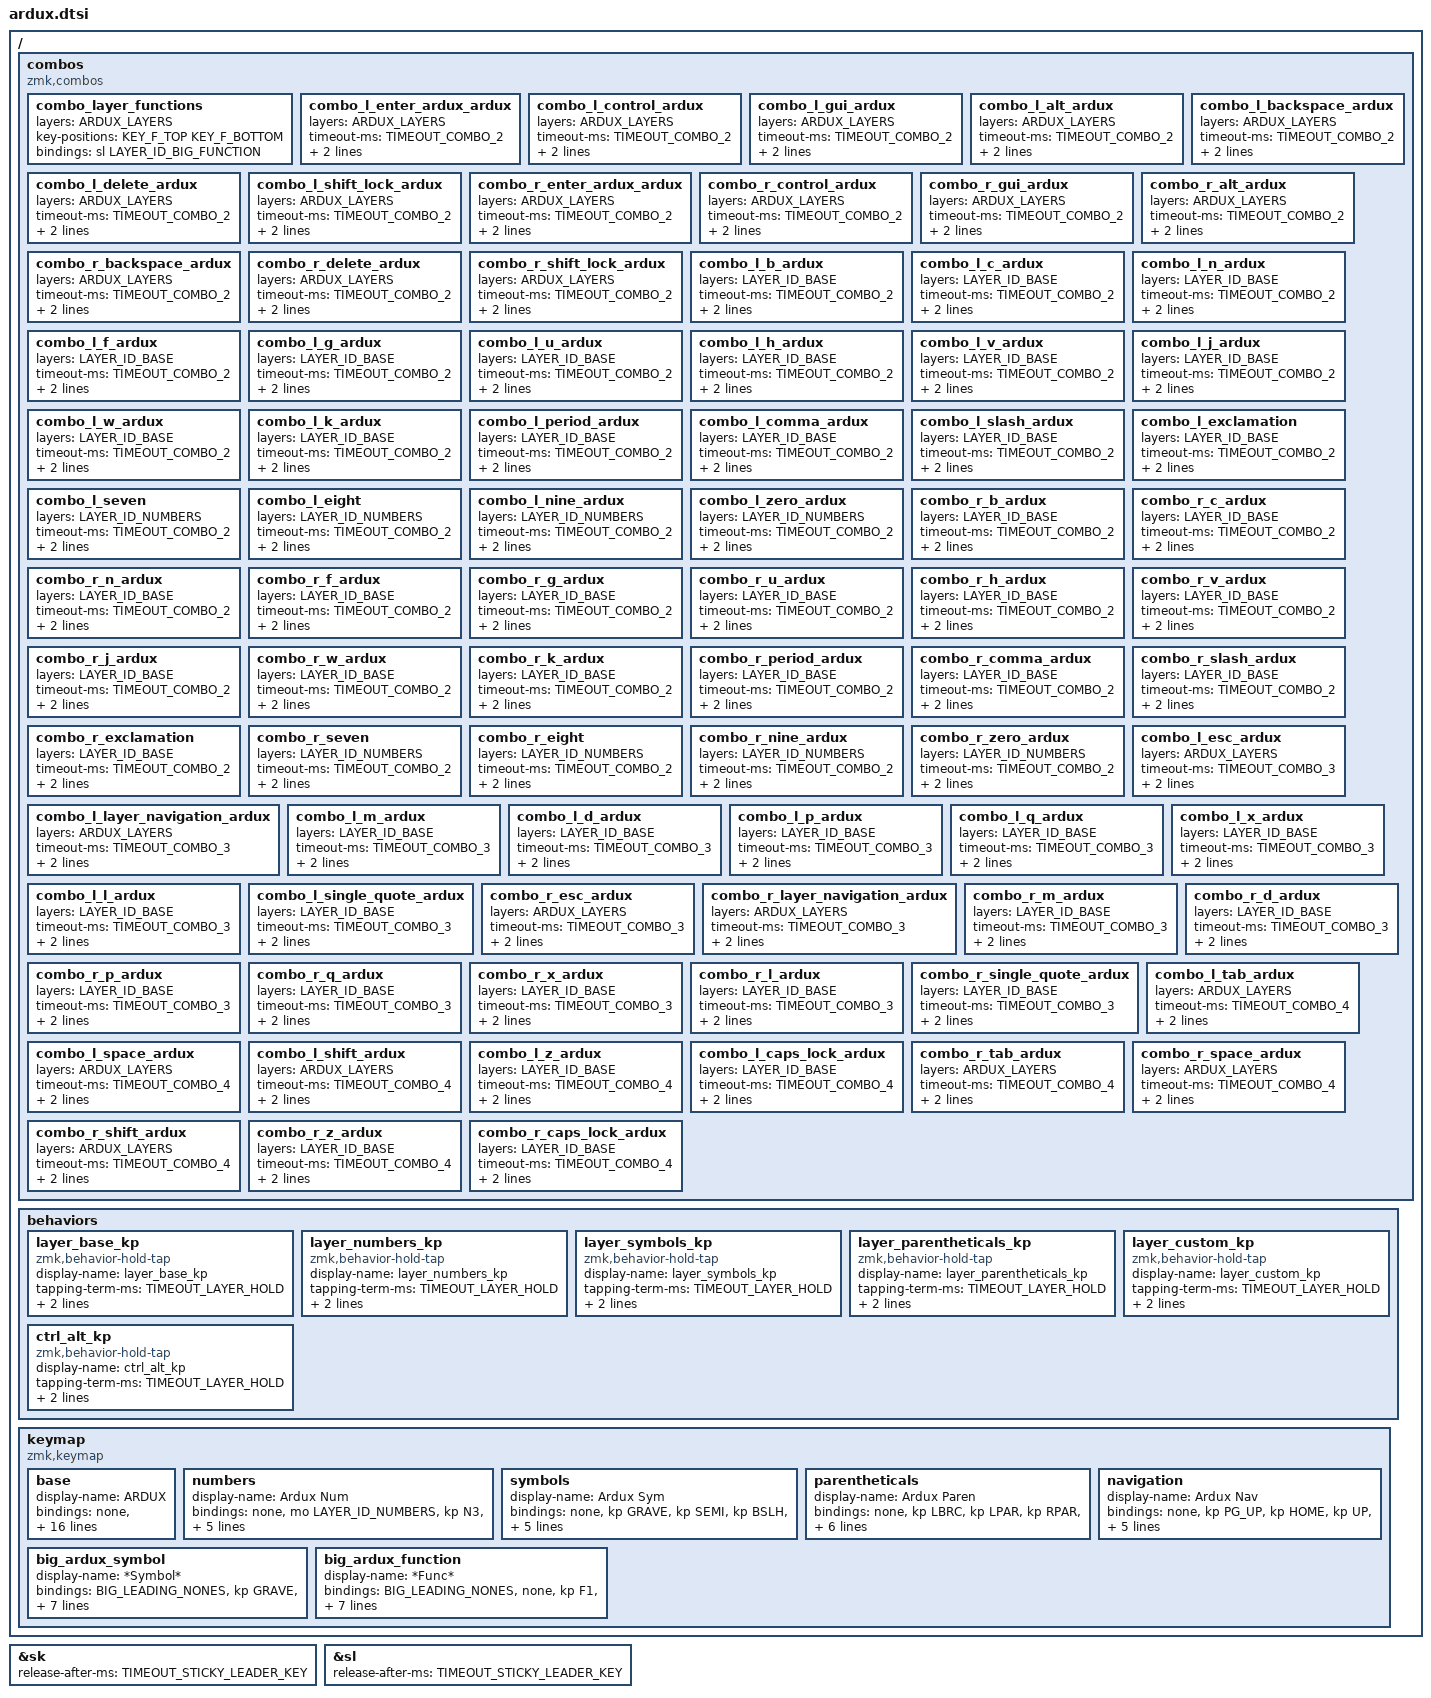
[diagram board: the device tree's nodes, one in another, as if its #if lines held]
/*
 * Copyright (c) 2021 Mike "KemoNine" Crosson
 *
 * SPDX-License-Identifier: MIT
 */

#include <behaviors.dtsi>
#include <dt-bindings/zmk/keys.h>
#include <dt-bindings/zmk/outputs.h>

/*****************************************
 * Macros for filling in "&none" in the right places in the keymap for re-use needs
 *****************************************/
#define NONE0(X)
#define NONE1(X) X
#define NONE2(X) NONE1(X) X
#define NONE3(X) NONE2(X) X
#define NONE4(X) NONE3(X) X
#define NONE5(X) NONE4(X) X
#define NONE6(X) NONE5(X) X
#define NONE7(X) NONE6(X) X
#define NONE8(X) NONE7(X) X
#define NONE9(X) NONE8(X) X
#define NONE10(X) NONE9(X) X

#define NONE(HUNDREDS,TENS,ONES) \
  NONE##HUNDREDS(NONE10(NONE10(&none))) \
  NONE##TENS(NONE10(&none)) \
  NONE##ONES(&none)

/*****************************************
 * ARDUX website : https://www.ardux.io
 * Primary reference : https://www.ardux.io/_FILES/images/ARDUX.jpg
*****************************************/

/*****************************************
 * Setting up ARDUX comboing
 *   - Enabled right OR left handed orientation
 *   - Please note: A/E key positions should be on your INDEX finger
 *     - The online reference is for right handed use
 *     - When using the ARDUX layout left handed you'll want to ensure your keypositions are flipped along the Y axis
 *   - Update/adjust the key positions using your boards keymap 
 *     - See below for additional details
 *   - YOU MUST SET THE FOLLOWING CONFIG VALUES FOR THIS SETUP TO WORK PROPERLY IN YOUR BOARDS .conf FILE
 *     - CONFIG_ZMK_COMBO_MAX_COMBOS_PER_KEY=16
 *     - CONFIG_ZMK_COMBO_MAX_KEYS_PER_COMBO=8
 *     - CONFIG_ZMK_COMBO_MAX_PRESSED_COMBOS=8
 *****************************************/

/*****************************************
 * Define which layout you want to use
 *  ONLY ENABLE ONE OF THESE
*****************************************/
//#define ARDUX_RIGHT 1
//#define ARDUX_LEFT 1
//#define ARDUX_BIG 1
// If you use COLEMAK as your standard keyboard layout, you may want this
//     This define will make base ardux keys and N more in line with COLEMAK
// #define ARDUX_COLEMAK 1

/*****************************************
 * Define key positions used for combos
 * These definitions are used to define the various ARDUX combos
 * 
 * Please see the documentation on "combos" for details on how to find the proper key positions
 *
 * Default key positions are for a generic 4x2 keyboard and should NOT be used outright
 * DEFINE these definitions in your boards keymap BEFORE including ardux.dtsi
*****************************************/
// ARTS Row
// #define KEY_A 0
// #define KEY_R 1
// #define KEY_T 2
// #define KEY_S 3
// EYIO Row
// #define KEY_E 4
// #define KEY_Y 5
// #define KEY_I 6
// #define KEY_O 7
// Big ardux F1-12 layer keys for combo
// #define KEY_F_TOP -1
// #define KEY_F_BOTTOM -1


// Big ardux F1-12 layer keys for combo
// If using these, update offsets
// #define KEY_F_TOP 5
// #define KEY_F_BOTTOM 17



/*****************************************
 * Define custom BT layer extra keys
 *
 * You can override the 2 blank keys on the BT select layer by copy/pasting the below into your keymap
 *     *before* including the ardux.dtsfile
 * Once added to your keymap you can adjust these 2 keys as you see fit
*****************************************/
#if !defined ARDUX_BT_TOP
#define ARDUX_BT_TOP &out OUT_BLE
#endif
#if !defined ARDUX_BT_BOTTOM
#define ARDUX_BT_BOTTOM &out OUT_USB
#endif

/*****************************************
 * Define how long it takes for the combos/holds to 'time out'
 * See documentation on "combos" for more detail
 * THE COMBO TIMEOUTS MUST BE THE SAME
 *    https://github.com/zmkfirmware/zmk/issues/905
 *****************************************/
#if !defined TIMEOUT_COMBO_2
#define TIMEOUT_COMBO_2 50
#endif
#if !defined TIMEOUT_COMBO_3
#define TIMEOUT_COMBO_3 50
#endif
#if !defined TIMEOUT_COMBO_4
#define TIMEOUT_COMBO_4 50
#endif
#if !defined TIMEOUT_LAYER_HOLD
#define TIMEOUT_LAYER_HOLD 200
#endif
#if !defined TIMEOUT_STICKY_LEADER_KEY
#define TIMEOUT_STICKY_LEADER_KEY 5000
#endif
&sk {
	release-after-ms = <TIMEOUT_STICKY_LEADER_KEY>;
};
&sl { 
	release-after-ms = <TIMEOUT_STICKY_LEADER_KEY>;
};

/*****************************************
 * Define custom layer
 *
 * You can override this layer by copy/pasting the into your keymap *before* including the ardux.dtsi file
 * Once added to your keymap you can adjust as you see fit
*****************************************/
#if !defined ARDUX_LAYER_CUSTOM
#if defined ARDUX_RIGHT
#define ARDUX_LAYER_CUSTOM                                            \
		custom {                                                       \
			display-name = "Custom";                                          \
			bindings = <                                               \
				LEADING_NONES                                          \
				&kp C_MUTE &kp INS   &kp C_VOL_UP  &none               \
				MIDDLE_NONES                                           \
				&sk RSHFT  &kp PSCRN &kp C_VOL_DN  &mo LAYER_ID_CUSTOM \
				TRAILING_NONES                                         \
			>;                                                         \
		};
#endif
#if defined ARDUX_LEFT
#define ARDUX_LAYER_CUSTOM                                            \
		custom {                                                       \
			display-name = "Custom";                                          \
			bindings = <                                               \
				LEADING_NONES                                          \
				&none               &kp C_VOL_UP  &kp INS   &kp C_MUTE \
				MIDDLE_NONES                                           \
				&mo LAYER_ID_CUSTOM &kp C_VOL_DN  &kp PSCRN &sk RSHFT  \
				TRAILING_NONES                                         \
			>;                                                         \
		};
#endif
#endif

/*****************************************
 * Define base layer chars for 'standard ARDUX' or 'COLEMAK' inspired (you can add more by following the pattern below)
 * Turn on the ARDUX_COLEMAK definition above if you want this change
 *****************************************/
// Default ARTSEY

// #define ARDUX_BASE_A A
// #define ARDUX_BASE_R R
// #define ARDUX_BASE_T T
// #define ARDUX_BASE_S S
// #define ARDUX_BASE_E E
// #define ARDUX_BASE_Y Y
// #define ARDUX_BASE_I I
// #define ARDUX_BASE_O O
// #define ARDUX_COMBO_N N

// My Colemak ARTSEY
// Currently stock, but consider improvements from https://www.keyboard-layout-editor.com/#/gists/3949ff5171bbd401532929f5c0ae5fcd
// Also consider: swap top + bottom row based on side of hand, so your home row always matches your 'normal' layout
#define ARDUX_BASE_A T
#define ARDUX_BASE_R S
#define ARDUX_BASE_T R
#define ARDUX_BASE_S A
#define ARDUX_BASE_E N
#define ARDUX_BASE_Y E
#define ARDUX_BASE_I I
#define ARDUX_BASE_O O
#define ARDUX_COMBO_N Y

/*****************************************
 * Layer IDs used by the ARDUX keymap
 * Do NOT change these and do NOT change the order of the layers as shown below
 *****************************************/
// Define ARDUX_LAYER in your own keymap
//#define LAYER_ID_GLOBAL ( ARDUX_LAYER - 1 ) // This seems wrong, and is never referenced
#define LAYER_ID_BASE ARDUX_LAYER
#define LAYER_ID_NUMBERS ( ARDUX_LAYER + 1 )
#define LAYER_ID_SYMBOLS ( ARDUX_LAYER + 2 )
#define LAYER_ID_PARENTHETICALS ( ARDUX_LAYER + 3 )
#define LAYER_ID_NAVIGATION ( ARDUX_LAYER + 4 )
#define LAYER_ID_BT_SEL ( ARDUX_LAYER + 5 )
#define LAYER_ID_CUSTOM ( ARDUX_LAYER + 6 )
#define LAYER_ID_BIG_SYM ( ARDUX_LAYER + 7 )
#define LAYER_ID_BIG_FUNCTION ( ARDUX_LAYER + 8 )

/*****************************************
 * Standard ARDUX combo definitions
 * These should NOT be changed and are global in scope
 *****************************************/
/ {
	combos {
		compatible = "zmk,combos";
		/*****************************************
		 * 2 key combos
		 *****************************************/
		 // ARDUX_LAYERS is currently defined in my own keymap
		// Function layer doesn't apply to non-big ardux presently
		#if defined ARDUX_BIG
		combo_layer_functions { layers = ARDUX_LAYERS; key-positions = <KEY_F_TOP KEY_F_BOTTOM>; bindings = <&sl LAYER_ID_BIG_FUNCTION>; };
		#endif
		combo_l_enter_ardux_ardux      { layers = ARDUX_LAYERS; timeout-ms = <TIMEOUT_COMBO_2>; key-positions = <KEY_L_A KEY_L_E>; bindings = <&kp ENTER>; };
		combo_l_control_ardux    { layers = ARDUX_LAYERS; timeout-ms = <TIMEOUT_COMBO_2>; key-positions = <KEY_L_E KEY_L_S>; bindings = <&sk LCTRL>; };
		combo_l_gui_ardux        { layers = ARDUX_LAYERS; timeout-ms = <TIMEOUT_COMBO_2>; key-positions = <KEY_L_Y KEY_L_S>; bindings = <&sk LGUI>; };
		combo_l_alt_ardux        { layers = ARDUX_LAYERS; timeout-ms = <TIMEOUT_COMBO_2>; key-positions = <KEY_L_I KEY_L_S>; bindings = <&sk LALT>; };
		combo_l_backspace_ardux  { layers = ARDUX_LAYERS; timeout-ms = <TIMEOUT_COMBO_2>; key-positions = <KEY_L_E KEY_L_R>; bindings = <&kp BACKSPACE>; };
		combo_l_delete_ardux     { layers = ARDUX_LAYERS; timeout-ms = <TIMEOUT_COMBO_2>; key-positions = <KEY_L_I KEY_L_R>; bindings = <&kp DELETE>; };
		combo_l_shift_lock_ardux { layers = ARDUX_LAYERS; timeout-ms = <TIMEOUT_COMBO_2>; key-positions = <KEY_L_R KEY_L_Y>; bindings = <&kt LSHFT>; };

		combo_r_enter_ardux_ardux      { layers = ARDUX_LAYERS; timeout-ms = <TIMEOUT_COMBO_2>; key-positions = <KEY_R_A KEY_R_E>; bindings = <&kp ENTER>; };
		combo_r_control_ardux    { layers = ARDUX_LAYERS; timeout-ms = <TIMEOUT_COMBO_2>; key-positions = <KEY_R_E KEY_R_S>; bindings = <&sk LCTRL>; };
		combo_r_gui_ardux        { layers = ARDUX_LAYERS; timeout-ms = <TIMEOUT_COMBO_2>; key-positions = <KEY_R_Y KEY_R_S>; bindings = <&sk LGUI>; };
		combo_r_alt_ardux        { layers = ARDUX_LAYERS; timeout-ms = <TIMEOUT_COMBO_2>; key-positions = <KEY_R_I KEY_R_S>; bindings = <&sk LALT>; };
		combo_r_backspace_ardux  { layers = ARDUX_LAYERS; timeout-ms = <TIMEOUT_COMBO_2>; key-positions = <KEY_R_E KEY_R_R>; bindings = <&kp BACKSPACE>; };
		combo_r_delete_ardux     { layers = ARDUX_LAYERS; timeout-ms = <TIMEOUT_COMBO_2>; key-positions = <KEY_R_I KEY_R_R>; bindings = <&kp DELETE>; };
		combo_r_shift_lock_ardux { layers = ARDUX_LAYERS; timeout-ms = <TIMEOUT_COMBO_2>; key-positions = <KEY_R_R KEY_R_Y>; bindings = <&kt LSHFT>; };


		combo_l_b_ardux           { layers = <LAYER_ID_BASE>; timeout-ms = <TIMEOUT_COMBO_2>; key-positions = <KEY_L_E KEY_L_O>; bindings = <&kp B>; };
		combo_l_c_ardux           { layers = <LAYER_ID_BASE>; timeout-ms = <TIMEOUT_COMBO_2>; key-positions = <KEY_L_E KEY_L_Y>; bindings = <&kp C>; };
		combo_l_n_ardux           { layers = <LAYER_ID_BASE>; timeout-ms = <TIMEOUT_COMBO_2>; key-positions = <KEY_L_I KEY_L_O>; bindings = <&kp ARDUX_COMBO_N>; };
		combo_l_f_ardux           { layers = <LAYER_ID_BASE>; timeout-ms = <TIMEOUT_COMBO_2>; key-positions = <KEY_L_A KEY_L_R>; bindings = <&kp F>; };
		combo_l_g_ardux           { layers = <LAYER_ID_BASE>; timeout-ms = <TIMEOUT_COMBO_2>; key-positions = <KEY_L_R KEY_L_T>; bindings = <&kp G>; };
		combo_l_u_ardux           { layers = <LAYER_ID_BASE>; timeout-ms = <TIMEOUT_COMBO_2>; key-positions = <KEY_L_Y KEY_L_I>; bindings = <&kp U>; };
		combo_l_h_ardux           { layers = <LAYER_ID_BASE>; timeout-ms = <TIMEOUT_COMBO_2>; key-positions = <KEY_L_E KEY_L_I>; bindings = <&kp H>; };
		combo_l_v_ardux           { layers = <LAYER_ID_BASE>; timeout-ms = <TIMEOUT_COMBO_2>; key-positions = <KEY_L_R KEY_L_S>; bindings = <&kp V>; };
		combo_l_j_ardux           { layers = <LAYER_ID_BASE>; timeout-ms = <TIMEOUT_COMBO_2>; key-positions = <KEY_L_T KEY_L_S>; bindings = <&kp J>; };
		combo_l_w_ardux           { layers = <LAYER_ID_BASE>; timeout-ms = <TIMEOUT_COMBO_2>; key-positions = <KEY_L_A KEY_L_S>; bindings = <&kp W>; };
		combo_l_k_ardux           { layers = <LAYER_ID_BASE>; timeout-ms = <TIMEOUT_COMBO_2>; key-positions = <KEY_L_Y KEY_L_O>; bindings = <&kp K>; };
		combo_l_period_ardux       { layers = <LAYER_ID_BASE>; timeout-ms = <TIMEOUT_COMBO_2>; key-positions = <KEY_L_A KEY_L_Y>; bindings = <&kp PERIOD>; };
		combo_l_comma_ardux       { layers = <LAYER_ID_BASE>; timeout-ms = <TIMEOUT_COMBO_2>; key-positions = <KEY_L_A KEY_L_I>; bindings = <&kp COMMA>; };
		combo_l_slash_ardux       { layers = <LAYER_ID_BASE>; timeout-ms = <TIMEOUT_COMBO_2>; key-positions = <KEY_L_A KEY_L_O>; bindings = <&kp SLASH>; };
		combo_l_exclamation { layers = <LAYER_ID_BASE>; timeout-ms = <TIMEOUT_COMBO_2>; key-positions = <KEY_L_T KEY_L_I>; bindings = <&kp EXCL>; };
		
		combo_l_seven { layers = <LAYER_ID_NUMBERS>; timeout-ms = <TIMEOUT_COMBO_2>; key-positions = <KEY_L_A KEY_L_R>; bindings = <&kp N7>; };
		combo_l_eight { layers = <LAYER_ID_NUMBERS>; timeout-ms = <TIMEOUT_COMBO_2>; key-positions = <KEY_L_R KEY_L_T>; bindings = <&kp N8>; };
		combo_l_nine_ardux  { layers = <LAYER_ID_NUMBERS>; timeout-ms = <TIMEOUT_COMBO_2>; key-positions = <KEY_L_E KEY_L_Y>; bindings = <&kp N9>; };
		combo_l_zero_ardux  { layers = <LAYER_ID_NUMBERS>; timeout-ms = <TIMEOUT_COMBO_2>; key-positions = <KEY_L_Y KEY_L_I>; bindings = <&kp N0>; };


		combo_r_b_ardux           { layers = <LAYER_ID_BASE>; timeout-ms = <TIMEOUT_COMBO_2>; key-positions = <KEY_R_E KEY_R_O>; bindings = <&kp B>; };
		combo_r_c_ardux           { layers = <LAYER_ID_BASE>; timeout-ms = <TIMEOUT_COMBO_2>; key-positions = <KEY_R_E KEY_R_Y>; bindings = <&kp C>; };
		combo_r_n_ardux           { layers = <LAYER_ID_BASE>; timeout-ms = <TIMEOUT_COMBO_2>; key-positions = <KEY_R_I KEY_R_O>; bindings = <&kp ARDUX_COMBO_N>; };
		combo_r_f_ardux           { layers = <LAYER_ID_BASE>; timeout-ms = <TIMEOUT_COMBO_2>; key-positions = <KEY_R_A KEY_R_R>; bindings = <&kp F>; };
		combo_r_g_ardux           { layers = <LAYER_ID_BASE>; timeout-ms = <TIMEOUT_COMBO_2>; key-positions = <KEY_R_R KEY_R_T>; bindings = <&kp G>; };
		combo_r_u_ardux           { layers = <LAYER_ID_BASE>; timeout-ms = <TIMEOUT_COMBO_2>; key-positions = <KEY_R_Y KEY_R_I>; bindings = <&kp U>; };
		combo_r_h_ardux           { layers = <LAYER_ID_BASE>; timeout-ms = <TIMEOUT_COMBO_2>; key-positions = <KEY_R_E KEY_R_I>; bindings = <&kp H>; };
		combo_r_v_ardux           { layers = <LAYER_ID_BASE>; timeout-ms = <TIMEOUT_COMBO_2>; key-positions = <KEY_R_R KEY_R_S>; bindings = <&kp V>; };
		combo_r_j_ardux           { layers = <LAYER_ID_BASE>; timeout-ms = <TIMEOUT_COMBO_2>; key-positions = <KEY_R_T KEY_R_S>; bindings = <&kp J>; };
		combo_r_w_ardux           { layers = <LAYER_ID_BASE>; timeout-ms = <TIMEOUT_COMBO_2>; key-positions = <KEY_R_A KEY_R_S>; bindings = <&kp W>; };
		combo_r_k_ardux           { layers = <LAYER_ID_BASE>; timeout-ms = <TIMEOUT_COMBO_2>; key-positions = <KEY_R_Y KEY_R_O>; bindings = <&kp K>; };
		combo_r_period_ardux       { layers = <LAYER_ID_BASE>; timeout-ms = <TIMEOUT_COMBO_2>; key-positions = <KEY_R_A KEY_R_Y>; bindings = <&kp PERIOD>; };
		combo_r_comma_ardux       { layers = <LAYER_ID_BASE>; timeout-ms = <TIMEOUT_COMBO_2>; key-positions = <KEY_R_A KEY_R_I>; bindings = <&kp COMMA>; };
		combo_r_slash_ardux       { layers = <LAYER_ID_BASE>; timeout-ms = <TIMEOUT_COMBO_2>; key-positions = <KEY_R_A KEY_R_O>; bindings = <&kp SLASH>; };
		combo_r_exclamation { layers = <LAYER_ID_BASE>; timeout-ms = <TIMEOUT_COMBO_2>; key-positions = <KEY_R_T KEY_R_I>; bindings = <&kp EXCL>; };
		
		combo_r_seven { layers = <LAYER_ID_NUMBERS>; timeout-ms = <TIMEOUT_COMBO_2>; key-positions = <KEY_R_A KEY_R_R>; bindings = <&kp N7>; };
		combo_r_eight { layers = <LAYER_ID_NUMBERS>; timeout-ms = <TIMEOUT_COMBO_2>; key-positions = <KEY_R_R KEY_R_T>; bindings = <&kp N8>; };
		combo_r_nine_ardux  { layers = <LAYER_ID_NUMBERS>; timeout-ms = <TIMEOUT_COMBO_2>; key-positions = <KEY_R_E KEY_R_Y>; bindings = <&kp N9>; };
		combo_r_zero_ardux  { layers = <LAYER_ID_NUMBERS>; timeout-ms = <TIMEOUT_COMBO_2>; key-positions = <KEY_R_Y KEY_R_I>; bindings = <&kp N0>; };

		/*****************************************
		 * 3 key combos
		 *****************************************/
		combo_l_esc_ardux              { layers = ARDUX_LAYERS; timeout-ms = <TIMEOUT_COMBO_3>; key-positions = <KEY_L_A KEY_L_R KEY_L_O>; bindings = <&kp ESC>; };
		combo_l_layer_navigation_ardux { layers = ARDUX_LAYERS; timeout-ms = <TIMEOUT_COMBO_3>; key-positions = <KEY_L_R KEY_L_E KEY_L_I>; bindings = <&tog LAYER_ID_NAVIGATION>; };

		combo_l_m_ardux            { layers = <LAYER_ID_BASE>; timeout-ms = <TIMEOUT_COMBO_3>; key-positions = <KEY_L_Y KEY_L_I KEY_L_O>; bindings = <&kp M>; };
		combo_l_d_ardux            { layers = <LAYER_ID_BASE>; timeout-ms = <TIMEOUT_COMBO_3>; key-positions = <KEY_L_A KEY_L_R KEY_L_T>; bindings = <&kp D>; };
		combo_l_p_ardux            { layers = <LAYER_ID_BASE>; timeout-ms = <TIMEOUT_COMBO_3>; key-positions = <KEY_L_E KEY_L_I KEY_L_O>; bindings = <&kp P>; };
		combo_l_q_ardux            { layers = <LAYER_ID_BASE>; timeout-ms = <TIMEOUT_COMBO_3>; key-positions = <KEY_L_A KEY_L_T KEY_L_S>; bindings = <&kp Q>; };
		combo_l_x_ardux            { layers = <LAYER_ID_BASE>; timeout-ms = <TIMEOUT_COMBO_3>; key-positions = <KEY_L_R KEY_L_T KEY_L_S>; bindings = <&kp X>; };
		combo_l_l_ardux            { layers = <LAYER_ID_BASE>; timeout-ms = <TIMEOUT_COMBO_3>; key-positions = <KEY_L_E KEY_L_Y KEY_L_I>; bindings = <&kp L>; };
		combo_l_single_quote_ardux { layers = <LAYER_ID_BASE>; timeout-ms = <TIMEOUT_COMBO_3>; key-positions = <KEY_L_A KEY_L_Y KEY_L_I>; bindings = <&kp SQT>; };

		combo_r_esc_ardux              { layers = ARDUX_LAYERS; timeout-ms = <TIMEOUT_COMBO_3>; key-positions = <KEY_R_A KEY_R_R KEY_R_O>; bindings = <&kp ESC>; };
		combo_r_layer_navigation_ardux { layers = ARDUX_LAYERS; timeout-ms = <TIMEOUT_COMBO_3>; key-positions = <KEY_R_R KEY_R_E KEY_R_I>; bindings = <&tog LAYER_ID_NAVIGATION>; };
		combo_r_m_ardux            { layers = <LAYER_ID_BASE>; timeout-ms = <TIMEOUT_COMBO_3>; key-positions = <KEY_R_Y KEY_R_I KEY_R_O>; bindings = <&kp M>; };
		combo_r_d_ardux            { layers = <LAYER_ID_BASE>; timeout-ms = <TIMEOUT_COMBO_3>; key-positions = <KEY_R_A KEY_R_R KEY_R_T>; bindings = <&kp D>; };
		combo_r_p_ardux            { layers = <LAYER_ID_BASE>; timeout-ms = <TIMEOUT_COMBO_3>; key-positions = <KEY_R_E KEY_R_I KEY_R_O>; bindings = <&kp P>; };
		combo_r_q_ardux            { layers = <LAYER_ID_BASE>; timeout-ms = <TIMEOUT_COMBO_3>; key-positions = <KEY_R_A KEY_R_T KEY_R_S>; bindings = <&kp Q>; };
		combo_r_x_ardux            { layers = <LAYER_ID_BASE>; timeout-ms = <TIMEOUT_COMBO_3>; key-positions = <KEY_R_R KEY_R_T KEY_R_S>; bindings = <&kp X>; };
		combo_r_l_ardux            { layers = <LAYER_ID_BASE>; timeout-ms = <TIMEOUT_COMBO_3>; key-positions = <KEY_R_E KEY_R_Y KEY_R_I>; bindings = <&kp L>; };
		combo_r_single_quote_ardux { layers = <LAYER_ID_BASE>; timeout-ms = <TIMEOUT_COMBO_3>; key-positions = <KEY_R_A KEY_R_Y KEY_R_I>; bindings = <&kp SQT>; };
		
		/*****************************************
		 * 4 key combos
		 *****************************************/
		combo_l_tab_ardux             { layers = ARDUX_LAYERS; timeout-ms = <TIMEOUT_COMBO_4>; key-positions = <KEY_L_A KEY_L_R KEY_L_T KEY_L_O>; bindings = <&kp TAB>; };
		combo_l_space_ardux           { layers = ARDUX_LAYERS; timeout-ms = <TIMEOUT_COMBO_4>; key-positions = <KEY_L_E KEY_L_Y KEY_L_I KEY_L_O>; bindings = <&kp SPACE>; };
		combo_l_shift_ardux           { layers = ARDUX_LAYERS; timeout-ms = <TIMEOUT_COMBO_4>; key-positions = <KEY_L_E KEY_L_R KEY_L_T KEY_L_S>; bindings = <&sk LSHFT>; };
		combo_l_z_ardux         { layers = <LAYER_ID_BASE>; timeout-ms = <TIMEOUT_COMBO_4>; key-positions = <KEY_L_A KEY_L_R KEY_L_T KEY_L_S>; bindings = <&kp Z>; };
		combo_l_caps_lock_ardux { layers = <LAYER_ID_BASE>; timeout-ms = <TIMEOUT_COMBO_4>; key-positions = <KEY_L_O KEY_L_I KEY_L_Y KEY_L_A>; bindings = <&kp CAPS>; };

		combo_r_tab_ardux             { layers = ARDUX_LAYERS; timeout-ms = <TIMEOUT_COMBO_4>; key-positions = <KEY_R_A KEY_R_R KEY_R_T KEY_R_O>; bindings = <&kp TAB>; };
		combo_r_space_ardux           { layers = ARDUX_LAYERS; timeout-ms = <TIMEOUT_COMBO_4>; key-positions = <KEY_R_E KEY_R_Y KEY_R_I KEY_R_O>; bindings = <&kp SPACE>; };
		combo_r_shift_ardux           { layers = ARDUX_LAYERS; timeout-ms = <TIMEOUT_COMBO_4>; key-positions = <KEY_R_E KEY_R_R KEY_R_T KEY_R_S>; bindings = <&sk LSHFT>; };
		combo_r_z_ardux         { layers = <LAYER_ID_BASE>; timeout-ms = <TIMEOUT_COMBO_4>; key-positions = <KEY_R_A KEY_R_R KEY_R_T KEY_R_S>; bindings = <&kp Z>; };
		combo_r_caps_lock_ardux { layers = <LAYER_ID_BASE>; timeout-ms = <TIMEOUT_COMBO_4>; key-positions = <KEY_R_O KEY_R_I KEY_R_Y KEY_R_A>; bindings = <&kp CAPS>; };
	};
};

/*****************************************
 * Standard ARDUX layer activation definitions
 * These should NOT be changed and are global in scope
 *****************************************/
/ {
	behaviors {
		layer_base_kp: layer_base_kp { compatible = "zmk,behavior-hold-tap"; display-name = "layer_base_kp";
						#binding-cells = <2>; tapping-term-ms = <TIMEOUT_LAYER_HOLD>; flavor = "tap-preferred";
						bindings = <&mo>, <&kp>; };
		layer_numbers_kp: layer_numbers_kp { compatible = "zmk,behavior-hold-tap"; display-name = "layer_numbers_kp";
						#binding-cells = <2>; tapping-term-ms = <TIMEOUT_LAYER_HOLD>; flavor = "tap-preferred";
						bindings = <&mo>, <&kp>; };
		layer_symbols_kp: layer_symbols_kp { compatible = "zmk,behavior-hold-tap"; display-name = "layer_symbols_kp";
						#binding-cells = <2>; tapping-term-ms = <TIMEOUT_LAYER_HOLD>; flavor = "tap-preferred";
						bindings = <&mo>, <&kp>; };
		layer_parentheticals_kp: layer_parentheticals_kp { compatible = "zmk,behavior-hold-tap"; display-name = "layer_parentheticals_kp";
						#binding-cells = <2>; tapping-term-ms = <TIMEOUT_LAYER_HOLD>; flavor = "tap-preferred";
						bindings = <&mo>, <&kp>; };
		layer_custom_kp: layer_custom_kp { compatible = "zmk,behavior-hold-tap"; display-name = "layer_custom_kp";
						#binding-cells = <2>; tapping-term-ms = <TIMEOUT_LAYER_HOLD>; flavor = "tap-preferred";
						bindings = <&mo>, <&kp>; };
		ctrl_alt_kp: ctrl_alt_kp { compatible = "zmk,behavior-hold-tap"; display-name = "ctrl_alt_kp";
						#binding-cells = <2>; tapping-term-ms = <TIMEOUT_LAYER_HOLD>; flavor = "tap-preferred";
						bindings = <&sk>, <&sk>; };
	};
};

/*****************************************
 * Standard ARDUX layer definitions
 * !!!!!!!!!! FOR RIGHT HANDED USE !!!!!!!!!!
 *****************************************/
/ {
	keymap {
		compatible = "zmk,keymap";

		base {
			display-name = "ARDUX";
			bindings = <
			// Left top
			&none 
			&layer_numbers_kp LAYER_ID_NUMBERS ARDUX_BASE_S        &kp ARDUX_BASE_T     &kp ARDUX_BASE_R     &layer_parentheticals_kp LAYER_ID_PARENTHETICALS ARDUX_BASE_A
			&none
				
			// Right top
			&none
			&layer_parentheticals_kp LAYER_ID_PARENTHETICALS ARDUX_BASE_A  &kp ARDUX_BASE_R     &kp ARDUX_BASE_T     &layer_numbers_kp LAYER_ID_NUMBERS ARDUX_BASE_S 
			&none

			// Left bottom
			&none
			&layer_custom_kp LAYER_ID_CUSTOM ARDUX_BASE_O          &kp ARDUX_BASE_I     &kp ARDUX_BASE_Y     &layer_symbols_kp LAYER_ID_SYMBOLS ARDUX_BASE_E
			&none

			// Right bottom
			&none
			&layer_symbols_kp LAYER_ID_SYMBOLS ARDUX_BASE_E                &kp ARDUX_BASE_Y     &kp ARDUX_BASE_I     &layer_custom_kp LAYER_ID_CUSTOM ARDUX_BASE_O 
			&none

			TRAILING_NONES
			>;
		};

		numbers {
			display-name = "Ardux Num";
			bindings = <
				// Left top
				&none 
				&mo LAYER_ID_NUMBERS &kp N3 &kp N2 &kp N1 
				&none

				// Right top			
				&none 
				&kp N1      &kp N2    &kp N3    &mo LAYER_ID_NUMBERS 
				&none

				// Left bottom
				&none 
				&none &kp N6    &kp N5    &kp N4 
				&none

				// Right bottom
				&none
				&kp N4 &kp N5    &kp N6    &none 
				&none

				TRAILING_NONES
			>;
		};
		symbols {
			display-name = "Ardux Sym";
			bindings = <
				// Left top
				&none 
				&kp GRAVE &kp SEMI  &kp BSLH  &kp EXCL
				&none

				// Right top
				&none
				&kp EXCL &kp BSLH  &kp SEMI  &kp GRAVE 
				&none

				// Left bottom
				&none
				&kp EQUAL  &kp MINUS &kp QMARK &mo LAYER_ID_SYMBOLS
				&none

				// Right bottom
				&none
				&mo LAYER_ID_SYMBOLS &kp QMARK &kp MINUS &kp EQUAL 
				&none

				TRAILING_NONES
			>;
		};
		parentheticals {
			display-name = "Ardux Paren";
			bindings = <
				// Left top
				&none
				&kp LBRC &kp LPAR  &kp RPAR  &mo LAYER_ID_PARENTHETICALS
				&none

				// Right top
				&none
				&mo LAYER_ID_PARENTHETICALS &kp LPAR  &kp RPAR  &kp LBRC
				&none

				// Left bottom
				&none
				&kp RBRC &kp LBKT  &kp RBKT  &none
				&none

				// Right bottom
				&none
				&none &kp LBKT  &kp RBKT  &kp RBRC
				&none

				TRAILING_NONES
			>;
		};
		navigation {
			display-name = "Ardux Nav";
			bindings = <
				// Left top
				&none
				&kp PG_UP &kp HOME  &kp UP    &kp END
				&none

				// Right top
				&none
				&kp HOME &kp UP &kp END   &kp PG_UP
				&none

				// Left bottom
				&none
				&kp PG_DN &kp LEFT  &kp DOWN  &kp RIGHT
				&none

				// Right bottom
				&none
				&kp LEFT &kp DOWN  &kp RIGHT &kp PG_DN
				&none

				TRAILING_NONES
			>;
		};
		// bt {
		// 	display-name = "Ardux BT";
		// 	bindings = <
		// 		LEADING_NONES
		// 		&bt BT_SEL 0 &bt BT_SEL 1 &bt BT_SEL 2 ARDUX_BT_TOP
		// 		MIDDLE_NONES
		// 		&bt BT_SEL 3 &bt BT_SEL 4 &bt BT_SEL 5 ARDUX_BT_BOTTOM
		// 		TRAILING_NONES
		// 	>;
		// };
		#if defined ARDUX_BIG
		big_ardux_symbol {
			display-name = "*Symbol*";
			bindings = <
				BIG_LEADING_NONES
				&kp GRAVE &kp HASH  &kp LBRC &kp RBRC &kp CARET
				BIG_BETWEEN_ROW_ONE_TWO_NONES
				&kp BSLH  &kp DLLR  &kp LPAR &kp RPAR &kp AMPS
				BIG_BETWEEN_ROW_TWO_THREE_NONES
				&kp PIPE  &kp PRCNT &kp LBKT &kp RBKT &kp ASTRK
				BIG_BETWEEN_ROW_THREE_THUMBS
				&trans    &kp SEMI  &none
				BIG_TRAILING_NONES
			>;
		};
		big_ardux_function {
			display-name = "*Func*";
			bindings = <
				BIG_LEADING_NONES
				&none  &kp F1 &kp F2  &kp F3  &kp F4
				BIG_BETWEEN_ROW_ONE_TWO_NONES
				&none  &kp F5 &kp F6  &kp F7  &kp F8
				BIG_BETWEEN_ROW_TWO_THREE_NONES
				&none  &kp F9 &kp F10 &kp F11 &kp F12
				BIG_BETWEEN_ROW_THREE_THUMBS
				&trans &none   &none
				BIG_TRAILING_NONES
			>;
		};
		#endif
	};
};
